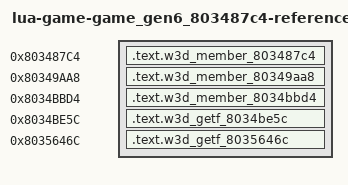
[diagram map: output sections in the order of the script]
/* Generated reference-only placements. All bodies are source-built. */
OUTPUT_FORMAT("elf32-powerpc")
OUTPUT_ARCH(powerpc)
ENTRY(w3d_member_803487c4)
_SDA_BASE_ = 0x804b2540;
_SDA2_BASE_ = 0x804c2540;
SECTIONS {
  .text.w3d_member_803487c4 0x803487c4 : { *(.text.w3d_member_803487c4) }
  .text.w3d_member_80349aa8 0x80349aa8 : { *(.text.w3d_member_80349aa8) }
  .text.w3d_member_8034bbd4 0x8034bbd4 : { *(.text.w3d_member_8034bbd4) }
  .text.w3d_getf_8034be5c 0x8034be5c : { *(.text.w3d_getf_8034be5c) }
  .text.w3d_getf_8035646c 0x8035646c : { *(.text.w3d_getf_8035646c) }
  /DISCARD/ : { *(.text*) *(.rodata*) *(.data*) *(.bss*) *(.sdata*) *(.sbss*) *(.comment) }
}
